# KM1M7CF16 register map
Vendor: Nuvoton Technology Corporation Japan; Series: KM1M7CF; File version: 1.0.3
CPU: CM7 r1p2, little endian, MPU, FPU, double-precision FPU, I-cache, D-cache, ITCM, DTCM, 4 interrupt priority bits
Registers are 32-bit, read-write, no defined reset value unless marked. A register's access mark holds for its fields unless they carry their own. Offsets are from the block's base; [hi:lo] are bit positions; 'fields as' and 'values as' point back to an identical list.

## PORT — I/O Port
Base 0x4005A000
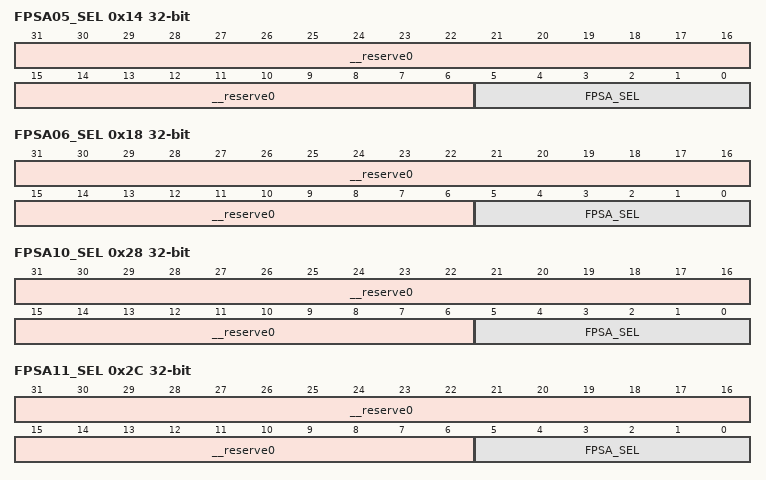
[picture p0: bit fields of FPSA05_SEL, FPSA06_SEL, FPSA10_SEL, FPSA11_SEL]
0x14 FPSA05_SEL access per field — FPSA05 Function Selection Register
  [31:6] __reserve0 ro — "0" is always read out.
  [5:0] FPSA_SEL rw — FPSAn function selection
0x18 FPSA06_SEL access per field — FPSA06 Function Selection Register
  fields as FPSA05_SEL
0x28 FPSA10_SEL access per field — FPSA10 Function Selection Register
  fields as FPSA05_SEL
0x2C FPSA11_SEL access per field — FPSA11 Function Selection Register
  fields as FPSA05_SEL
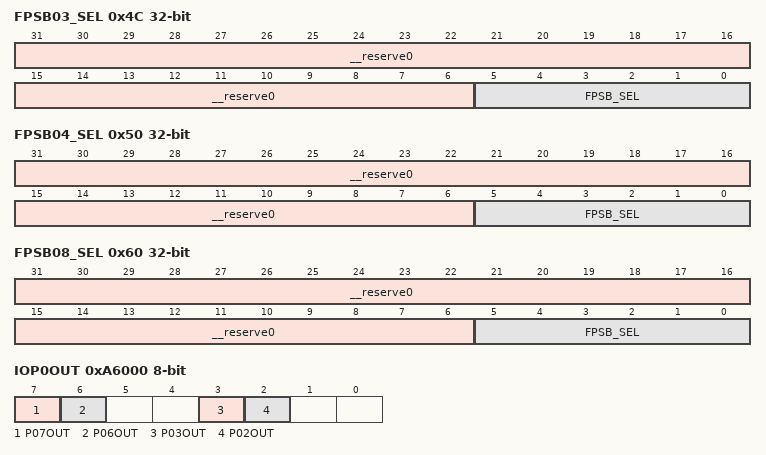
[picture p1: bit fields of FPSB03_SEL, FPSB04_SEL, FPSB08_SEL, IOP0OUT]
0x4C FPSB03_SEL access per field — FPSB03 Function Selection Register
  [31:6] __reserve0 ro — "0" is always read out.
  [5:0] FPSB_SEL rw — FPSBn function selection
0x50 FPSB04_SEL access per field — FPSB04 Function Selection Register
  fields as FPSB03_SEL
0x60 FPSB08_SEL access per field — FPSB08 Function Selection Register
  fields as FPSB03_SEL
0xA6000 IOP0OUT 8-bit — Port 0 Output Register
  [7] P07OUT — Set output data of P07
  [6] P06OUT — Set output data of P06
  [3] P03OUT — Set output data of P03
  [2] P02OUT — Set output data of P02
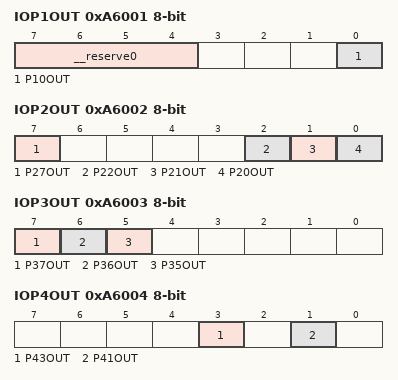
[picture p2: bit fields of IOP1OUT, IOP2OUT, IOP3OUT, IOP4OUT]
0xA6001 IOP1OUT 8-bit access per field — Port 1 Output Register
  [7:4] __reserve0 ro — "0" is always read out.
  [0] P10OUT rw — Set output data of P10
0xA6002 IOP2OUT 8-bit — Port 2 Output Register
  [7] P27OUT — Set output data of P27
  [2] P22OUT — Set output data of P22
  [1] P21OUT — Set output data of P21
  [0] P20OUT — Set output data of P20
0xA6003 IOP3OUT 8-bit — Port 3 Output Register
  [7] P37OUT — Set output data of P37
  [6] P36OUT — Set output data of P36
  [5] P35OUT — Set output data of P35
0xA6004 IOP4OUT 8-bit — Port 4 Output Register
  [3] P43OUT — Set output data of P43
  [1] P41OUT — Set output data of P41
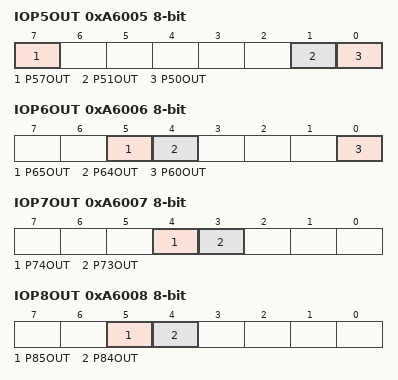
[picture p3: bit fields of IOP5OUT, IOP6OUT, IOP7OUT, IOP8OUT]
0xA6005 IOP5OUT 8-bit — Port 5 Output Register
  [7] P57OUT — Set output data of P57
  [1] P51OUT — Set output data of P51
  [0] P50OUT — Set output data of P50
0xA6006 IOP6OUT 8-bit — Port 6 Output Register
  [5] P65OUT — Set output data of P65
  [4] P64OUT — Set output data of P64
  [0] P60OUT — Set output data of P60
0xA6007 IOP7OUT 8-bit — Port 7 Output Register
  [4] P74OUT — Set output data of P74
  [3] P73OUT — Set output data of P73
0xA6008 IOP8OUT 8-bit — Port 8 Output Register
  [5] P85OUT — Set output data of P85
  [4] P84OUT — Set output data of P84
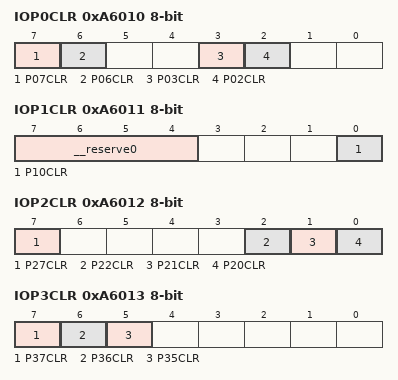
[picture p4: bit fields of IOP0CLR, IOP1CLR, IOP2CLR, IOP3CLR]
0xA6010 IOP0CLR 8-bit wo — Port 0 Output Clear Register
  [7] P07CLR — Clear P07OUT
  [6] P06CLR — Clear P06OUT
  [3] P03CLR — Clear P03OUT
  [2] P02CLR — Clear P02OUT
0xA6011 IOP1CLR 8-bit access per field — Port 1 Output Clear Register
  [7:4] __reserve0 ro — "0" is always read out.
  [0] P10CLR wo — Clear P10OUT
0xA6012 IOP2CLR 8-bit wo — Port 2 Output Clear Register
  [7] P27CLR — Clear P27OUT
  [2] P22CLR — Clear P22OUT
  [1] P21CLR — Clear P21OUT
  [0] P20CLR — Clear P20OUT
0xA6013 IOP3CLR 8-bit wo — Port 3 Output Clear Register
  [7] P37CLR — Clear P37OUT
  [6] P36CLR — Clear P36OUT
  [5] P35CLR — Clear P35OUT
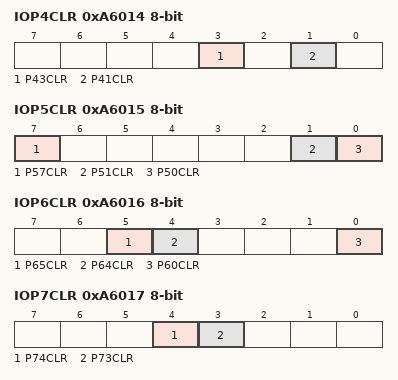
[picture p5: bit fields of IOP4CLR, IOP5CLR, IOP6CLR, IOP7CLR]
0xA6014 IOP4CLR 8-bit wo — Port 4 Output Clear Register
  [3] P43CLR — Clear P43OUT
  [1] P41CLR — Clear P41OUT
0xA6015 IOP5CLR 8-bit wo — Port 5 Output Clear Register
  [7] P57CLR — Clear P57OUT
  [1] P51CLR — Clear P51OUT
  [0] P50CLR — Clear P50OUT
0xA6016 IOP6CLR 8-bit wo — Port 6 Output Clear Register
  [5] P65CLR — Clear P65OUT
  [4] P64CLR — Clear P64OUT
  [0] P60CLR — Clear P60OUT
0xA6017 IOP7CLR 8-bit wo — Port 7 Output Clear Register
  [4] P74CLR — Clear P74OUT
  [3] P73CLR — Clear P73OUT
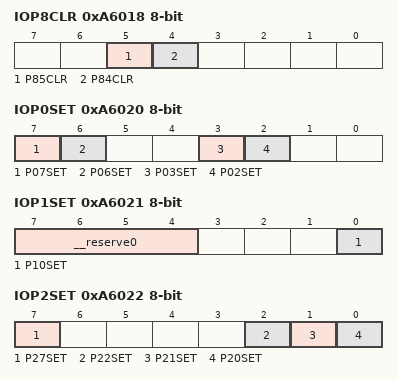
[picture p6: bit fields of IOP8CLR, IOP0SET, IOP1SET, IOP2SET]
0xA6018 IOP8CLR 8-bit wo — Port 8 Output Clear Register
  [5] P85CLR — Clear P85OUT
  [4] P84CLR — Clear P84OUT
0xA6020 IOP0SET 8-bit wo — Port 0 Output Set Register
  [7] P07SET — Set P07OUT
  [6] P06SET — Set P06OUT
  [3] P03SET — Set P03OUT
  [2] P02SET — Set P02OUT
0xA6021 IOP1SET 8-bit access per field — Port 1 Output Set Register
  [7:4] __reserve0 ro — "0" is always read out.
  [0] P10SET wo — Set P10OUT
0xA6022 IOP2SET 8-bit wo — Port 2 Output Set Register
  [7] P27SET — Set P27OUT
  [2] P22SET — Set P22OUT
  [1] P21SET — Set P21OUT
  [0] P20SET — Set P20OUT
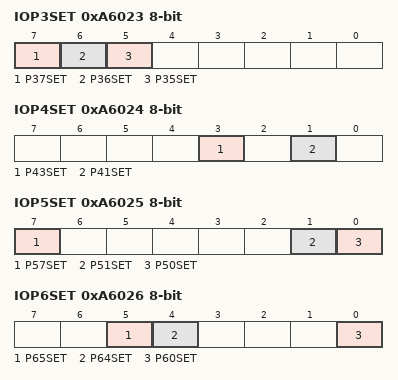
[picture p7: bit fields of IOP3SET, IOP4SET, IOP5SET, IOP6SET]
0xA6023 IOP3SET 8-bit wo — Port 3 Output Set Register
  [7] P37SET — Set P37OUT
  [6] P36SET — Set P36OUT
  [5] P35SET — Set P35OUT
0xA6024 IOP4SET 8-bit wo — Port 4 Output Set Register
  [3] P43SET — Set P43OUT
  [1] P41SET — Set P41OUT
0xA6025 IOP5SET 8-bit wo — Port 5 Output Set Register
  [7] P57SET — Set P57OUT
  [1] P51SET — Set P51OUT
  [0] P50SET — Set P50OUT
0xA6026 IOP6SET 8-bit wo — Port 6 Output Set Register
  [5] P65SET — Set P65OUT
  [4] P64SET — Set P64OUT
  [0] P60SET — Set P60OUT
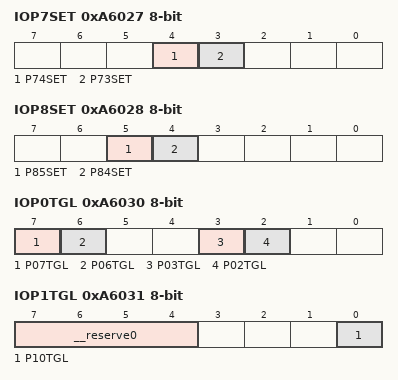
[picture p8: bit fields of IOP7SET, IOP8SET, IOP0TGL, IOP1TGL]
0xA6027 IOP7SET 8-bit wo — Port 7 Output Set Register
  [4] P74SET — Set P74OUT
  [3] P73SET — Set P73OUT
0xA6028 IOP8SET 8-bit wo — Port 8 Output Set Register
  [5] P85SET — Set P85OUT
  [4] P84SET — Set P84OUT
0xA6030 IOP0TGL 8-bit wo — Port 0 Output Toggle Register
  [7] P07TGL — Invert P07OUT
  [6] P06TGL — Invert P06OUT
  [3] P03TGL — Invert P03OUT
  [2] P02TGL — Invert P02OUT
0xA6031 IOP1TGL 8-bit access per field — Port 1 Output Toggle Register
  [7:4] __reserve0 ro — "0" is always read out.
  [0] P10TGL wo — Invert P10OUT
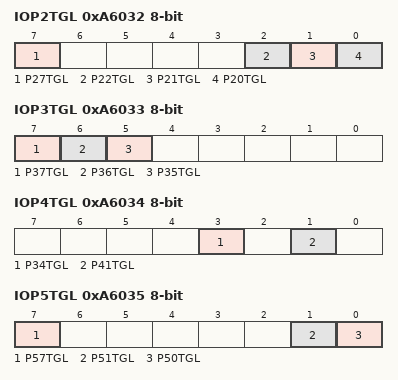
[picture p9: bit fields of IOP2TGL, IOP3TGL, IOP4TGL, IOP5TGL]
0xA6032 IOP2TGL 8-bit wo — Port 2 Output Toggle Register
  [7] P27TGL — Invert P27OUT
  [2] P22TGL — Invert P22OUT
  [1] P21TGL — Invert P21OUT
  [0] P20TGL — Invert P20OUT
0xA6033 IOP3TGL 8-bit wo — Port 3 Output Toggle Register
  [7] P37TGL — Invert P37OUT
  [6] P36TGL — Invert P36OUT
  [5] P35TGL — Invert P35OUT
0xA6034 IOP4TGL 8-bit wo — Port 4 Output Toggle Register
  [3] P34TGL — Invert P43OUT
  [1] P41TGL — Invert P41OUT
0xA6035 IOP5TGL 8-bit wo — Port 5 Output Toggle Register
  [7] P57TGL — Invert P57OUT
  [1] P51TGL — Invert P51OUT
  [0] P50TGL — Invert P50OUT
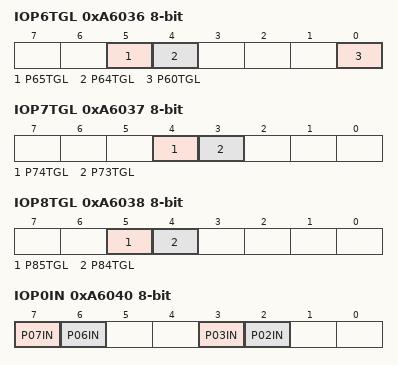
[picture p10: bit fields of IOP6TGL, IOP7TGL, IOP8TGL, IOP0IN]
0xA6036 IOP6TGL 8-bit wo — Port 6 Output Toggle Register
  [5] P65TGL — Invert P65OUT
  [4] P64TGL — Invert P64OUT
  [0] P60TGL — Invert P60OUT
0xA6037 IOP7TGL 8-bit wo — Port 7 Output Toggle Register
  [4] P74TGL — Invert P74OUT
  [3] P73TGL — Invert P73OUT
0xA6038 IOP8TGL 8-bit wo — Port 8 Output Toggle Register
  [5] P85TGL — Invert P85OUT
  [4] P84TGL — Invert P84OUT
0xA6040 IOP0IN 8-bit ro — Port 0 Input Register
  [7] P07IN — Input data of P07 is read out.
  [6] P06IN — Input data of P06 is read out.
  [3] P03IN — Input data of P03 is read out.
  [2] P02IN — Input data of P02 is read out.
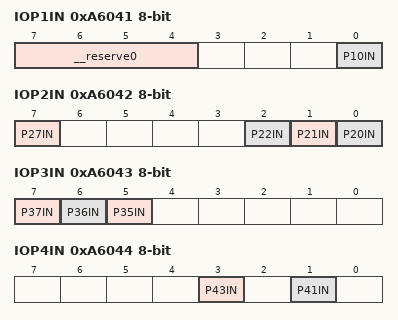
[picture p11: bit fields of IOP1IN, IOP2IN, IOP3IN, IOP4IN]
0xA6041 IOP1IN 8-bit ro — Port 1 Input Register
  [7:4] __reserve0 — "0" is always read out.
  [0] P10IN — Input data of P10 is read out.
0xA6042 IOP2IN 8-bit ro — Port 2 Input Register
  [7] P27IN — Input data of P27 is read out.
  [2] P22IN — Input data of P22 is read out.
  [1] P21IN — Input data of P21 is read out.
  [0] P20IN — Input data of P20 is read out.
0xA6043 IOP3IN 8-bit ro — Port 3 Input Register
  [7] P37IN — Input data of P37 is read out.
  [6] P36IN — Input data of P36 is read out.
  [5] P35IN — Input data of P35 is read out.
0xA6044 IOP4IN 8-bit ro — Port 4 Input Register
  [3] P43IN — Input data of P43 is read out.
  [1] P41IN — Input data of P41 is read out.
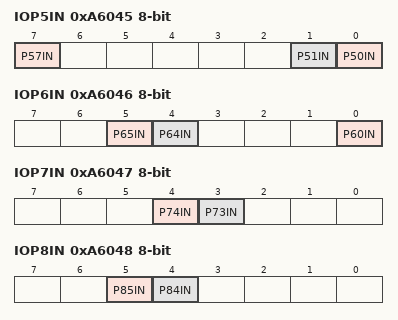
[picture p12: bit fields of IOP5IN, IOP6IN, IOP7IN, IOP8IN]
0xA6045 IOP5IN 8-bit ro — Port 5 Input Register
  [7] P57IN — Input data of P57 is read out.
  [1] P51IN — Input data of P51 is read out.
  [0] P50IN — Input data of P50 is read out.
0xA6046 IOP6IN 8-bit ro — Port 6 Input Register
  [5] P65IN — Input data of P65 is read out.
  [4] P64IN — Input data of P64 is read out.
  [0] P60IN — Input data of P60 is read out.
0xA6047 IOP7IN 8-bit ro — Port 7 Input Register
  [4] P74IN — Input data of P74 is read out.
  [3] P73IN — Input data of P73 is read out.
0xA6048 IOP8IN 8-bit ro — Port 8 Input Register
  [5] P85IN — Input data of P85 is read out.
  [4] P84IN — Input data of P84 is read out.
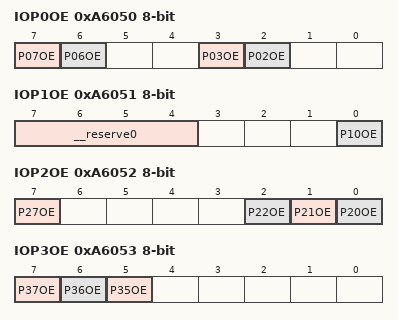
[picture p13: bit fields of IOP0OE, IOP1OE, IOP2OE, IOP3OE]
0xA6050 IOP0OE 8-bit — Port 0 Output Enable Register
  [7] P07OE — P07 output enable
  [6] P06OE — P06 output enable
  [3] P03OE — P03 output enable
  [2] P02OE — P02 output enable
0xA6051 IOP1OE 8-bit access per field — Port 1 Output Enable Register
  [7:4] __reserve0 ro — "0" is always read out.
  [0] P10OE rw — P10 output enable
0xA6052 IOP2OE 8-bit — Port 2 Output Enable Register
  [7] P27OE — P27 output enable
  [2] P22OE — P22 output enable
  [1] P21OE — P21 output enable
  [0] P20OE — P20 output enable
0xA6053 IOP3OE 8-bit — Port 3 Output Enable Register
  [7] P37OE — P37 output enable
  [6] P36OE — P36 output enable
  [5] P35OE — P35 output enable
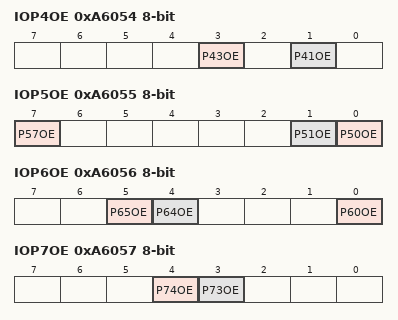
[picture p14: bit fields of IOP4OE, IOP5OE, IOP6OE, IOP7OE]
0xA6054 IOP4OE 8-bit — Port 4 Output Enable Register
  [3] P43OE — P43 output enable
  [1] P41OE — P41 output enable
0xA6055 IOP5OE 8-bit — Port 5 Output Enable Register
  [7] P57OE — P57 output enable
  [1] P51OE — P51 output enable
  [0] P50OE — P50 output enable
0xA6056 IOP6OE 8-bit — Port 6 Output Enable Register
  [5] P65OE — P65 output enable
  [4] P64OE — P64 output enable
  [0] P60OE — P60 output enable
0xA6057 IOP7OE 8-bit — Port 7 Output Enable Register
  [4] P74OE — P74 output enable
  [3] P73OE — P73 output enable
0xA6058 IOP8OE 8-bit — Port 8 Output Enable Register
  [5] P85OE — P85 output enable
  [4] P84OE — P84 output enable
0xA6060 IOP0IE 8-bit — Port 0 Input Enable Register
  [7] P07IE — P07 input enable
  [6] P06IE — P06 input enable
  [3] P03IE — P03 input enable
  [2] P02IE — P02 input enable
0xA6061 IOP1IE 8-bit access per field — Port 1 Input Enable Register
  [7:4] __reserve0 ro — "0" is always read out.
  [0] P10IE rw — P10 input enable
0xA6062 IOP2IE 8-bit — Port 2 Input Enable Register
  [7] P27IE — P27 input enable
  [2] P22IE — P22 input enable
  [1] P21IE — P21 input enable
  [0] P20IE — P20 input enable
0xA6063 IOP3IE 8-bit — Port 3 Input Enable Register
  [7] P37IE — P37 input enable
  [6] P36IE — P36 input enable
  [5] P35IE — P35 input enable
0xA6064 IOP4IE 8-bit — Port 4 Input Enable Register
  [3] P43IE — P43 input enable
  [1] P41IE — P41 input enable
0xA6065 IOP5IE 8-bit — Port 5 Input Enable Register
  [7] P57IE — P57 input enable
  [1] P51IE — P51 input enable
  [0] P50IE — P50 input enable
0xA6066 IOP6IE 8-bit — Port 6 Input Enable Register
  [5] P65IE — P65 input enable
  [4] P64IE — P64 input enable
  [0] P60IE — P60 input enable
0xA6067 IOP7IE 8-bit — Port 7 Input Enable Register
  [4] P74IE — P74 input enable
  [3] P73IE — P73 input enable
0xA6068 IOP8IE 8-bit — Port 8 Input Enable Register
  [5] P85IE — P85 input enable
  [4] P84IE — P84 input enable
0xA6071 IOP1ODC 8-bit access per field — Port 1 Nch Open-drain Control Register
  [7:4] __reserve0 ro — "0" is always read out.
  [0] P10ODC rw — P10 Nch open-drain selection
0xA6075 IOP5ODC 8-bit access per field — Port 5 Nch Open-drain Control Register
  [7] P57ODC rw — P57 Nch open-drain selection
  [1:0] __reserve0 ro — "0" is always read out.
0xA6076 IOP6ODC 8-bit — Port 6 Nch Open-drain Control Register
  [5] P65ODC — P65 Nch open-drain selection
  [4] P64ODC — P64 Nch open-drain selection
  [0] P60ODC — P60 Nch open-drain selection
0xA6077 IOP7ODC 8-bit — Port 7 Nch Open-drain Control Register
  [4] P74ODC — P74 Nch open-drain selection
  [3] P73ODC — P73 Nch open-drain selection
0xA6080 IOP0MD — Port 0 Mode Register
  [31:28] P07MD — P07 function selection
  [27:24] P06MD — P06 function selection
  [15:12] P03MD — P03 function selection
  [11:8] P02MD — P02 function selection
0xA6084 IOP1MD access per field — Port 1 Mode Register
  [31:16] __reserve0 ro — "0" is always read out.
  [3:0] P10MD rw — P10 function selection
0xA6088 IOP2MD — Port 2 Mode Register
  [31:28] P27MD — P27 function selection
  [11:8] P22MD — P22 function selection
  [7:4] P21MD — P21 function selection
  [3:0] P20MD — P20 function selection
0xA608C IOP3MD — Port 3 Mode Register
  [31:28] P37MD — P37 function selection
  [27:24] P36MD — P36 function selection
  [23:20] P35MD — P35 function selection
0xA6090 IOP4MD — Port 4 Mode Register
  [15:12] P43MD — P43 function selection
  [7:4] P41MD — P41 function selection
0xA6094 IOP5MD — Port 5 Mode Register
  [31:28] P57MD — P57 function selection
  [7:4] P51MD — P51 function selection
  [3:0] P50MD — P50 function selection
0xA6098 IOP6MD — Port 6 Mode Register
  [23:20] P65MD — P65 function selection
  [19:16] P64MD — P64 function selection
  [3:0] P60MD — P60 function selection
0xA609C IOP7MD — Port 7 Mode Register
  [19:16] P74MD — P74 function selection
  [15:12] P73MD — P73 function selection
0xA60A0 IOP8MD — Port 8 Mode Register
  [23:20] P85MD — P85 function selection
  [19:16] P84MD — P84 function selection
0xA60C0 IOP0PLU 8-bit — Port 0 Pull-up Control Register
  [7] P07PLU — P07 pull-up resistor selection
  [6] P06PLU — P06 pull-up resistor selection
  [3] P03PLU — P03 pull-up resistor selection
  [2] P02PLU — P02 pull-up resistor selection
0xA60C1 IOP1PLU 8-bit access per field — Port 1 Pull-up Control Register
  [7:4] __reserve0 ro — "0" is always read out.
  [0] P10PLU rw — P10 pull-up resistor selection
0xA60C2 IOP2PLU 8-bit — Port 2 Pull-up Control Register
  [7] P27PLU — P27 pull-up resistor selection
  [2] P22PLU — P22 pull-up resistor selection
  [1] P21PLU — P21 pull-up resistor selection
  [0] P20PLU — P20 pull-up resistor selection
0xA60C3 IOP3PLU 8-bit — Port 3 Pull-up Control Register
  [7] P37PLU — P37 pull-up resistor selection
  [6] P36PLU — P36 pull-up resistor selection
  [5] P35PLU — P35 pull-up resistor selection
0xA60C4 IOP4PLU 8-bit — Port 4 Pull-up Control Register
  [3] P43PLU — P43 pull-up resistor selection
  [1] P41PLU — P41 pull-up resistor selection
0xA60C5 IOP5PLU 8-bit — Port 5 Pull-up Control Register
  [7] P57PLU — P57 pull-up resistor selection
  [1] P51PLU — P51 pull-up resistor selection
  [0] P50PLU — P50 pull-up resistor selection
0xA60C6 IOP6PLU 8-bit — Port 6 Pull-up Control Register
  [5] P65PLU — P65 pull-up resistor selection
  [4] P64PLU — P64 pull-up resistor selection
  [0] P60PLU — P60 pull-up resistor selection
0xA60C7 IOP7PLU 8-bit — Port 7 Pull-up Control Register
  [4] P74PLU — P74 pull-up resistor selection
  [3] P73PLU — P73 pull-up resistor selection
0xA60C8 IOP8PLU 8-bit — Port 8 Pull-up Control Register
  [5] P85PLU — P85 pull-up resistor selection
  [4] P84PLU — P84 pull-up resistor selection
0xA60D0 IOP0DRV 8-bit — Port 0 Output Current Capacity Control Register
  [7] P07DRV — P07 output current capacity selection
  [6] P06DRV — P06 output current capacity selection
  [3] P03DRV — P03 output current capacity selection
  [2] P02DRV — P02 output current capacity selection
0xA60D1 IOP1DRV 8-bit access per field — Port 1 Output Current Capacity Control Register
  [7:4] __reserve0 ro — "0" is always read out.
  [0] P10DRV rw — P10 output current capacity selection
0xA60D2 IOP2DRV 8-bit — Port 2 Output Current Capacity Control Register
  [7] P27DRV — P27 output current capacity selection
  [2] P22DRV — P22 output current capacity selection
  [1] P21DRV — P21 output current capacity selection
  [0] P20DRV — P20 output current capacity selection
0xA60D3 IOP3DRV 8-bit — Port 3 Output Current Capacity Control Register
  [7] P37DRV — P37 output current capacity selection
  [6] P36DRV — P36 output current capacity selection
  [5] P35DRV — P35 output current capacity selection
0xA60D4 IOP4DRV 8-bit — Port 4 Output Current Capacity Control Register
  [3] P43DRV — P43 output current capacity selection
  [1] P41DRV — P41 output current capacity selection
0xA60D5 IOP5DRV 8-bit — Port 5 Output Current Capacity Control Register
  [7] P57DRV — P57 output current capacity selection
  [1] P51DRV — P51 output current capacity selection
  [0] P50DRV — P50 output current capacity selection
0xA60D6 IOP6DRV 8-bit — Port 6 Output Current Capacity Control Register
  [5] P65DRV — P65 output current capacity selection
  [4] P64DRV — P64 output current capacity selection
  [0] P60DRV — P60 output current capacity selection
0xA60D7 IOP7DRV 8-bit — Port 7 Output Current Capacity Control Register
  [4] P74DRV — P74 output current capacity selection
  [3] P73DRV — P73 output current capacity selection
0xA60D8 IOP8DRV 8-bit — Port 8 Output Current Capacity Control Register
  [5] P85DRV — P85 output current capacity selection
  [4] P84DRV — P84 output current capacity selection
0xA60E5 IOP5ILV 8-bit access per field — Port 5 Input Level Selection Register
  [7] P57ILV rw — P57 Input level selection
  [6:0] __reserve0 ro — "0" is always read out.
0xA60E6 IOP6ILV 8-bit access per field — Port 6 Input Level Selection Register
  [7:1] __reserve0 ro — "0" is always read out.
  [0] P60ILV rw — P60 input level selection
